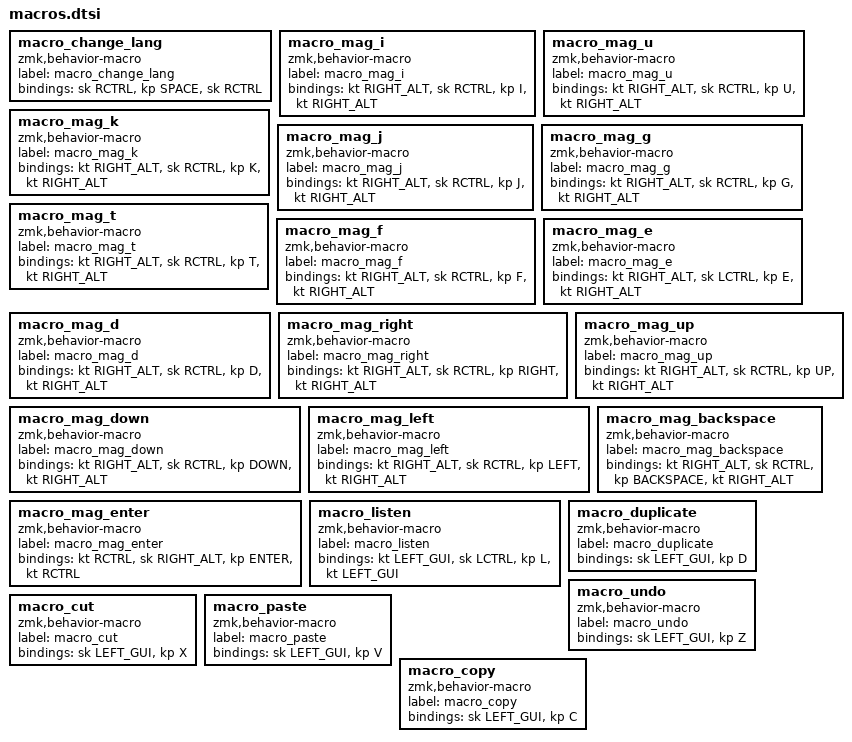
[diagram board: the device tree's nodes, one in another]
macro_change_lang: macro_change_lang{
compatible = "zmk,behavior-macro";
label = "macro_change_lang";
#binding-cells = <0>;
bindings = <&sk RCTRL>, <&kp SPACE>, <&sk RCTRL>;
};
macro_mag_i: macro_mag_i{
compatible = "zmk,behavior-macro";
label = "macro_mag_i";
#binding-cells = <0>;
bindings = <&kt RIGHT_ALT>, <&sk RCTRL>, <&kp I>, <&kt RIGHT_ALT>;
};
macro_mag_u: macro_mag_u{
compatible = "zmk,behavior-macro";
label = "macro_mag_u";
#binding-cells = <0>;
bindings = <&kt RIGHT_ALT>, <&sk RCTRL>, <&kp U>, <&kt RIGHT_ALT>;
};
macro_mag_k: macro_mag_k{
compatible = "zmk,behavior-macro";
label = "macro_mag_k";
#binding-cells = <0>;
bindings = <&kt RIGHT_ALT>, <&sk RCTRL>, <&kp K>, <&kt RIGHT_ALT>;
};
macro_mag_j: macro_mag_j{
compatible = "zmk,behavior-macro";
label = "macro_mag_j";
#binding-cells = <0>;
bindings = <&kt RIGHT_ALT>, <&sk RCTRL>, <&kp J>, <&kt RIGHT_ALT>;
};
macro_mag_g: macro_mag_g{
compatible = "zmk,behavior-macro";
label = "macro_mag_g";
#binding-cells = <0>;
bindings = <&kt RIGHT_ALT>, <&sk RCTRL>, <&kp G>, <&kt RIGHT_ALT>;
};
macro_mag_t: macro_mag_t{
compatible = "zmk,behavior-macro";
label = "macro_mag_t";
#binding-cells = <0>;
bindings = <&kt RIGHT_ALT>, <&sk RCTRL>, <&kp T>, <&kt RIGHT_ALT>;
};
macro_mag_f: macro_mag_f{
compatible = "zmk,behavior-macro";
label = "macro_mag_f";
#binding-cells = <0>;
bindings = <&kt RIGHT_ALT>, <&sk RCTRL>, <&kp F>, <&kt RIGHT_ALT>;
};
macro_mag_e: macro_mag_e{
compatible = "zmk,behavior-macro";
label = "macro_mag_e";
#binding-cells = <0>;
bindings = <&kt RIGHT_ALT>, <&sk LCTRL>, <&kp E>, <&kt RIGHT_ALT>;
};
macro_mag_d: macro_mag_d{
compatible = "zmk,behavior-macro";
label = "macro_mag_d";
#binding-cells = <0>;
bindings = <&kt RIGHT_ALT>, <&sk RCTRL>, <&kp D>, <&kt RIGHT_ALT>;
};
macro_mag_right: macro_mag_right{
compatible = "zmk,behavior-macro";
label = "macro_mag_right";
#binding-cells = <0>;
bindings = <&kt RIGHT_ALT>, <&sk RCTRL>, <&kp RIGHT>, <&kt RIGHT_ALT>;
};
macro_mag_up: macro_mag_up{
compatible = "zmk,behavior-macro";
label = "macro_mag_up";
#binding-cells = <0>;
bindings = <&kt RIGHT_ALT>, <&sk RCTRL>, <&kp UP>, <&kt RIGHT_ALT>;
};
macro_mag_down: macro_mag_down{
compatible = "zmk,behavior-macro";
label = "macro_mag_down";
#binding-cells = <0>;
bindings = <&kt RIGHT_ALT>, <&sk RCTRL>, <&kp DOWN>, <&kt RIGHT_ALT>;
};
macro_mag_left: macro_mag_left{
compatible = "zmk,behavior-macro";
label = "macro_mag_left";
#binding-cells = <0>;
bindings = <&kt RIGHT_ALT>, <&sk RCTRL>, <&kp LEFT>, <&kt RIGHT_ALT>;
};
macro_mag_backspace: macro_mag_backspace{
compatible = "zmk,behavior-macro";
label = "macro_mag_backspace";
#binding-cells = <0>;
bindings = <&kt RIGHT_ALT>, <&sk RCTRL>, <&kp BACKSPACE>, <&kt RIGHT_ALT>;
};
macro_mag_enter: macro_mag_enter{
compatible = "zmk,behavior-macro";
label = "macro_mag_enter";
#binding-cells = <0>;
bindings = <&kt RCTRL>, <&sk RIGHT_ALT>, <&kp ENTER>, <&kt RCTRL>;
};
macro_listen: macro_listen{
compatible = "zmk,behavior-macro";
label = "macro_listen";
#binding-cells = <0>;
bindings = <&kt LEFT_GUI>, <&sk LCTRL>, <&kp L>, <&kt LEFT_GUI>;
};
macro_duplicate: macro_duplicate{
compatible = "zmk,behavior-macro";
label = "macro_duplicate";
#binding-cells = <0>;
bindings = <&sk LEFT_GUI>, <&kp D>;
};
macro_undo: macro_undo{
compatible = "zmk,behavior-macro";
label = "macro_undo";
#binding-cells = <0>;
bindings = <&sk LEFT_GUI>, <&kp Z>;
};
macro_cut: macro_cut{
compatible = "zmk,behavior-macro";
label = "macro_cut";
#binding-cells = <0>;
bindings = <&sk LEFT_GUI>, <&kp X>;
};
macro_paste: macro_paste{
compatible = "zmk,behavior-macro";
label = "macro_paste";
#binding-cells = <0>;
bindings = <&sk LEFT_GUI>, <&kp V>;
};
macro_copy: macro_copy{
compatible = "zmk,behavior-macro";
label = "macro_copy";
#binding-cells = <0>;
bindings = <&sk LEFT_GUI>, <&kp C>;
};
